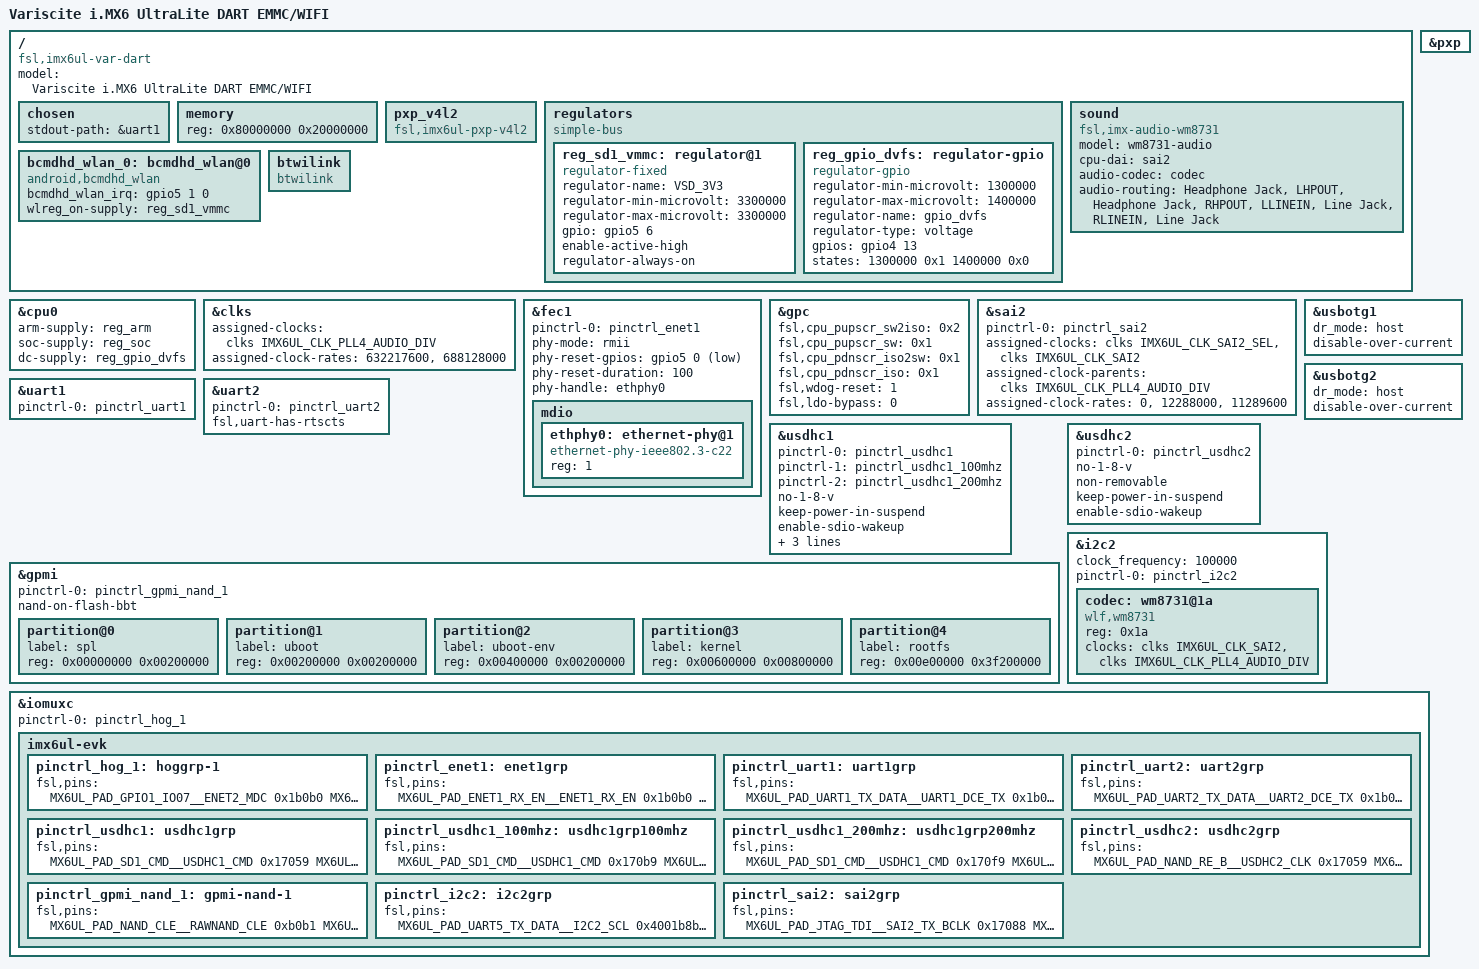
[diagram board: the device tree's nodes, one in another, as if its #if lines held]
/*
 * Copyright (C) 2015 Freescale Semiconductor, Inc.
 *
 * Copyright (C) 2015 Variscite Ltd. - http://www.variscite.com
 *
 * This program is free software; you can redistribute it and/or modify
 * it under the terms of the GNU General Public License version 2 as
 * published by the Free Software Foundation.
 */
/* #define WIFI */
/* #define EMMC */
/* #define  NAND  */
/dts-v1/;

#include <dt-bindings/input/input.h>
#include "imx6ul.dtsi"

/ {
#ifdef NAND
#ifdef WIFI
	model = "Variscite i.MX6 UltraLite DART NAND/WIFI";
#else
	model = "Variscite i.MX6 UltraLite DART NAND/SD";
#endif
#endif
#ifdef EMMC
#ifdef WIFI
	model = "Variscite i.MX6 UltraLite DART EMMC/WIFI";
#else
	model = "Variscite i.MX6 UltraLite DART EMMC/SD";
#endif
#endif
	compatible = "fsl,imx6ul-var-dart", "fsl,imx6ul";

	chosen {
		stdout-path = &uart1;
	};

	memory {
		reg = <0x80000000 0x20000000>;
	};

	pxp_v4l2 {
		compatible = "fsl,imx6ul-pxp-v4l2", "fsl,imx6sx-pxp-v4l2", "fsl,imx6sl-pxp-v4l2";
		status = "okay";
	};

	regulators {
		compatible = "simple-bus";
		#address-cells = <1>;
		#size-cells = <0>;

#ifdef WIFI
/* force VMMC1 to always on so BT can operate independently of Wi-Fi */
		reg_sd1_vmmc: regulator@1 {
			compatible = "regulator-fixed";
			regulator-name = "VSD_3V3";
			regulator-min-microvolt = <3300000>;
			regulator-max-microvolt = <3300000>;
			gpio = <&gpio5 6 GPIO_ACTIVE_HIGH>; 	/* WL_REG_ON: SNVS_TAMPER1 (gpio5_6) */
			enable-active-high;
			regulator-always-on;
		};

#endif
		reg_gpio_dvfs: regulator-gpio {
			compatible = "regulator-gpio";
			regulator-min-microvolt = <1300000>;
			regulator-max-microvolt = <1400000>;
			regulator-name = "gpio_dvfs";
			regulator-type = "voltage";
			gpios = <&gpio4 13 GPIO_ACTIVE_HIGH>;
			states = <1300000 0x1 1400000 0x0>;
		};
	};

	sound {
		compatible = "fsl,imx-audio-wm8731";
		model = "wm8731-audio";
		cpu-dai = <&sai2>;
		audio-codec = <&codec>;
		audio-routing =
			"Headphone Jack",	"LHPOUT",	
			"Headphone Jack", 	"RHPOUT",
			"LLINEIN", 			"Line Jack",
			"RLINEIN",			"Line Jack";
	};

#ifdef WIFI
	/* define hook for BCMDHD driver.   */
	/* Include WL_HOST_WAKE and WL_REG_ON GPIO's. */
	bcmdhd_wlan_0: bcmdhd_wlan@0 {
		compatible = "android,bcmdhd_wlan";
		/* WL_HOST_WAKE: ENET2_RX_ER (gpio5_01) */
		bcmdhd_wlan_irq = <&gpio5 1 0>;
		wlreg_on-supply = <&reg_sd1_vmmc>;
		
	};

	btwilink {
		compatible = "btwilink";
	};
#endif
};

&cpu0 {
	arm-supply = <&reg_arm>;
	soc-supply = <&reg_soc>;
	dc-supply = <&reg_gpio_dvfs>;
};

&clks {
	assigned-clocks = <&clks IMX6UL_CLK_PLL4_AUDIO_DIV>;
	assigned-clock-rates = <632217600>,<688128000>;
};

&fec1 {
	pinctrl-names = "default";
	pinctrl-0 = <&pinctrl_enet1>;
	phy-mode = "rmii";
	phy-reset-gpios=<&gpio5 0 1>;
	phy-reset-duration=<100>;
	phy-handle = <&ethphy0>;
	status = "okay";
	mdio {
		#address-cells = <1>;
		#size-cells = <0>;

		ethphy0: ethernet-phy@1 {
			compatible = "ethernet-phy-ieee802.3-c22";
			reg = <1>;
		};
	};
};

&gpc {
//ud1	fsl,cpu_pupscr_sw2iso = <0x1>;
//ud1	fsl,cpu_pupscr_sw = <0x0>;
	fsl,cpu_pupscr_sw2iso = <0x2>;
	fsl,cpu_pupscr_sw = <0x1>;
	fsl,cpu_pdnscr_iso2sw = <0x1>;
	fsl,cpu_pdnscr_iso = <0x1>;
	fsl,wdog-reset = <1>; /* watchdog select of reset source */
	fsl,ldo-bypass = <0>; /* DCDC, ldo-enable */
};

&pxp {
	status = "okay";
};

&sai2 {
	pinctrl-names = "default";
	pinctrl-0 = <&pinctrl_sai2>;
	assigned-clocks = <&clks IMX6UL_CLK_SAI2_SEL>,<&clks IMX6UL_CLK_SAI2>;
    	assigned-clock-parents = <&clks IMX6UL_CLK_PLL4_AUDIO_DIV>;
   	assigned-clock-rates = <0>, <12288000>,<11289600>;
	
	status = "okay";
};

/* Console Uart */
&uart1 {
	pinctrl-names = "default";
	pinctrl-0 = <&pinctrl_uart1>;
	status = "okay";
};

/* Bluetooth Uart */
&uart2 {
	pinctrl-names = "default";
	pinctrl-0 = <&pinctrl_uart2>;
	fsl,uart-has-rtscts;
	status = "okay";
};


	/* dr_mode: One of "host", "peripheral" or "otg". Defaults to "otg" */
&usbotg1 {
	dr_mode = "host";
	disable-over-current;
	status = "okay";
};

&usbotg2 {
	dr_mode = "host";
	disable-over-current;
	status = "okay";
};

#ifdef WIFI
/*  Wi-Fi/BT SD Card Slot Definition */
&usdhc1 {
	pinctrl-names = "default", "state_100mhz", "state_200mhz";
	pinctrl-0 = <&pinctrl_usdhc1>;
	pinctrl-1 = <&pinctrl_usdhc1_100mhz>;
	pinctrl-2 = <&pinctrl_usdhc1_200mhz>;
//	cd-gpios = <&gpio4 19 0>;
	no-1-8-v;
	keep-power-in-suspend;
	enable-sdio-wakeup;
	vmmc-supply = <&reg_sd1_vmmc>; 
	wifi-host;			 /* add hook for SD card detect mechanism */
	non-removable;
	status = "okay";
};
#endif

#ifdef NAND
&gpmi {
	pinctrl-names = "default";
	pinctrl-0 = <&pinctrl_gpmi_nand_1>;
	nand-on-flash-bbt;
	status = "okay";
	
	partition@0 {
		label = "spl";
		reg = <0x00000000 0x00200000>;
	};

	partition@1 {
		label = "uboot";
		reg = <0x00200000 0x00200000>;
	};

	partition@2 {
		label = "uboot-env";
		reg = <0x00400000 0x00200000>;
	};

	partition@3 {
		label = "kernel";
		reg = <0x00600000 0x00800000>;
	};

	partition@4 {
		label = "rootfs";
		reg = <0x00e00000 0x3f200000>;
	};
};

&usdhc2 {
	status = "disabled";
};
#endif

#ifdef EMMC
&usdhc2 {
	pinctrl-names = "default";
	pinctrl-0 = <&pinctrl_usdhc2>;
	no-1-8-v;
	non-removable;
	keep-power-in-suspend;
	enable-sdio-wakeup;
	status = "okay";
};
#endif

&i2c2 {
	clock_frequency = <100000>;
	pinctrl-names = "default";
	pinctrl-0 = <&pinctrl_i2c2>;
	status = "okay";
	
	codec: wm8731@1a {
		compatible = "wlf,wm8731";
		reg = <0x1a>;
		
		clocks = <&clks IMX6UL_CLK_SAI2>, <&clks IMX6UL_CLK_PLL4_AUDIO_DIV>;
		clock-names = "mclk","pll4";
	};
};

&iomuxc {
	pinctrl-names = "default";
	pinctrl-0 = <&pinctrl_hog_1>;
	imx6ul-evk {
		pinctrl_hog_1: hoggrp-1 {
			fsl,pins = <
				MX6UL_PAD_GPIO1_IO07__ENET2_MDC		0x1b0b0
				MX6UL_PAD_GPIO1_IO06__ENET2_MDIO	0x1b0b0
				MX6UL_PAD_SNVS_TAMPER4__GPIO5_IO04	0x1b0b0	/* BT Enable */
				MX6UL_PAD_SNVS_TAMPER0__GPIO5_IO00	0x1b0b0 /* Eth PHY Reset */
			>;
		};

		pinctrl_enet1: enet1grp {
			fsl,pins = <
				MX6UL_PAD_ENET1_RX_EN__ENET1_RX_EN	0x1b0b0
				MX6UL_PAD_ENET1_RX_ER__ENET1_RX_ER	0x1b0b0
				MX6UL_PAD_ENET1_RX_DATA0__ENET1_RDATA00	0x1b0b0
				MX6UL_PAD_ENET1_RX_DATA1__ENET1_RDATA01	0x1b0b0
				MX6UL_PAD_ENET1_TX_EN__ENET1_TX_EN	0x1b0b0
				MX6UL_PAD_ENET1_TX_DATA0__ENET1_TDATA00	0x1b0b0
				MX6UL_PAD_ENET1_TX_DATA1__ENET1_TDATA01	0x1b0b0
				MX6UL_PAD_ENET1_TX_CLK__ENET1_REF_CLK1	0x4001b031
			>;
		};

		pinctrl_uart1: uart1grp {
			fsl,pins = <
				MX6UL_PAD_UART1_TX_DATA__UART1_DCE_TX 0x1b0b1
				MX6UL_PAD_UART1_RX_DATA__UART1_DCE_RX 0x1b0b1
			>;
		};

		pinctrl_uart2: uart2grp {
			fsl,pins = <
				MX6UL_PAD_UART2_TX_DATA__UART2_DCE_TX	0x1b0b1
				MX6UL_PAD_UART2_RX_DATA__UART2_DCE_RX	0x1b0b1
				MX6UL_PAD_UART2_CTS_B__UART2_DCE_CTS	0x1b0b1
				MX6UL_PAD_UART2_RTS_B__UART2_DCE_RTS	0x1b0b1
			>;
		};

		pinctrl_usdhc1: usdhc1grp {
			fsl,pins = <
				MX6UL_PAD_SD1_CMD__USDHC1_CMD     0x17059
				MX6UL_PAD_SD1_CLK__USDHC1_CLK     0x17059
				MX6UL_PAD_SD1_DATA0__USDHC1_DATA0 0x17059
				MX6UL_PAD_SD1_DATA1__USDHC1_DATA1 0x17059
				MX6UL_PAD_SD1_DATA2__USDHC1_DATA2 0x17059
				MX6UL_PAD_SD1_DATA3__USDHC1_DATA3 0x17059
				MX6UL_PAD_CSI_VSYNC__GPIO4_IO19	  0x1b0b1  /* SD card detect */
				MX6UL_PAD_SNVS_TAMPER6__GPIO5_IO06 0x03029 /* WLAN enable */
			>;
		};

		pinctrl_usdhc1_100mhz: usdhc1grp100mhz {
			fsl,pins = <
				MX6UL_PAD_SD1_CMD__USDHC1_CMD     0x170b9
				MX6UL_PAD_SD1_CLK__USDHC1_CLK     0x100b9
				MX6UL_PAD_SD1_DATA0__USDHC1_DATA0 0x170b9
				MX6UL_PAD_SD1_DATA1__USDHC1_DATA1 0x170b9
				MX6UL_PAD_SD1_DATA2__USDHC1_DATA2 0x170b9
				MX6UL_PAD_SD1_DATA3__USDHC1_DATA3 0x170b9
				MX6UL_PAD_CSI_VSYNC__GPIO4_IO19	  0x1b0b1  /* SD card detect */
				MX6UL_PAD_SNVS_TAMPER6__GPIO5_IO06 0x03029 /* WLAN enable */
			>;
		};

		pinctrl_usdhc1_200mhz: usdhc1grp200mhz {
			fsl,pins = <
				MX6UL_PAD_SD1_CMD__USDHC1_CMD     0x170f9
				MX6UL_PAD_SD1_CLK__USDHC1_CLK     0x100f9
				MX6UL_PAD_SD1_DATA0__USDHC1_DATA0 0x170f9
				MX6UL_PAD_SD1_DATA1__USDHC1_DATA1 0x170f9
				MX6UL_PAD_SD1_DATA2__USDHC1_DATA2 0x170f9
				MX6UL_PAD_SD1_DATA3__USDHC1_DATA3 0x170f9
				MX6UL_PAD_CSI_VSYNC__GPIO4_IO19	  0x1b0b1  /* SD card detect */
				MX6UL_PAD_SNVS_TAMPER6__GPIO5_IO06 0x03029 /* WLAN enable */
			>;
		};
#ifdef EMMC
		pinctrl_usdhc2: usdhc2grp {
			fsl,pins = <
				MX6UL_PAD_NAND_RE_B__USDHC2_CLK     0x17059
				MX6UL_PAD_NAND_WE_B__USDHC2_CMD     0x17059
				MX6UL_PAD_NAND_DATA00__USDHC2_DATA0 0x17059
				MX6UL_PAD_NAND_DATA01__USDHC2_DATA1 0x17059
				MX6UL_PAD_NAND_DATA02__USDHC2_DATA2 0x17059
				MX6UL_PAD_NAND_DATA03__USDHC2_DATA3 0x17059
			>;
		};
#endif
#ifdef NAND
		pinctrl_gpmi_nand_1: gpmi-nand-1 {
			fsl,pins = <
				MX6UL_PAD_NAND_CLE__RAWNAND_CLE         0xb0b1
				MX6UL_PAD_NAND_ALE__RAWNAND_ALE         0xb0b1
				MX6UL_PAD_NAND_WP_B__RAWNAND_WP_B       0xb0b1
				MX6UL_PAD_NAND_READY_B__RAWNAND_READY_B 0xb000
				MX6UL_PAD_NAND_CE0_B__RAWNAND_CE0_B     0xb0b1
				MX6UL_PAD_NAND_CE1_B__RAWNAND_CE1_B     0xb0b1
				MX6UL_PAD_NAND_RE_B__RAWNAND_RE_B       0xb0b1
				MX6UL_PAD_NAND_WE_B__RAWNAND_WE_B       0xb0b1
				MX6UL_PAD_NAND_DATA00__RAWNAND_DATA00   0xb0b1
				MX6UL_PAD_NAND_DATA01__RAWNAND_DATA01   0xb0b1
				MX6UL_PAD_NAND_DATA02__RAWNAND_DATA02   0xb0b1
				MX6UL_PAD_NAND_DATA03__RAWNAND_DATA03   0xb0b1
				MX6UL_PAD_NAND_DATA04__RAWNAND_DATA04   0xb0b1
				MX6UL_PAD_NAND_DATA05__RAWNAND_DATA05   0xb0b1
				MX6UL_PAD_NAND_DATA06__RAWNAND_DATA06   0xb0b1
				MX6UL_PAD_NAND_DATA07__RAWNAND_DATA07   0xb0b1
			>;
		};
#endif

		pinctrl_i2c2: i2c2grp {
			fsl,pins = <
				MX6UL_PAD_UART5_TX_DATA__I2C2_SCL 0x4001b8b0
				MX6UL_PAD_UART5_RX_DATA__I2C2_SDA 0x4001b8b0
			>;
		};

		pinctrl_sai2: sai2grp {
			fsl,pins = <
				MX6UL_PAD_JTAG_TDI__SAI2_TX_BCLK	0x17088
				MX6UL_PAD_JTAG_TDO__SAI2_TX_SYNC	0x17088
				MX6UL_PAD_JTAG_TRST_B__SAI2_TX_DATA	0x11088
				MX6UL_PAD_JTAG_TCK__SAI2_RX_DATA	0x11088
				MX6UL_PAD_JTAG_TMS__CCM_CLKO1		0x17088
			>;
		};

	};
};

